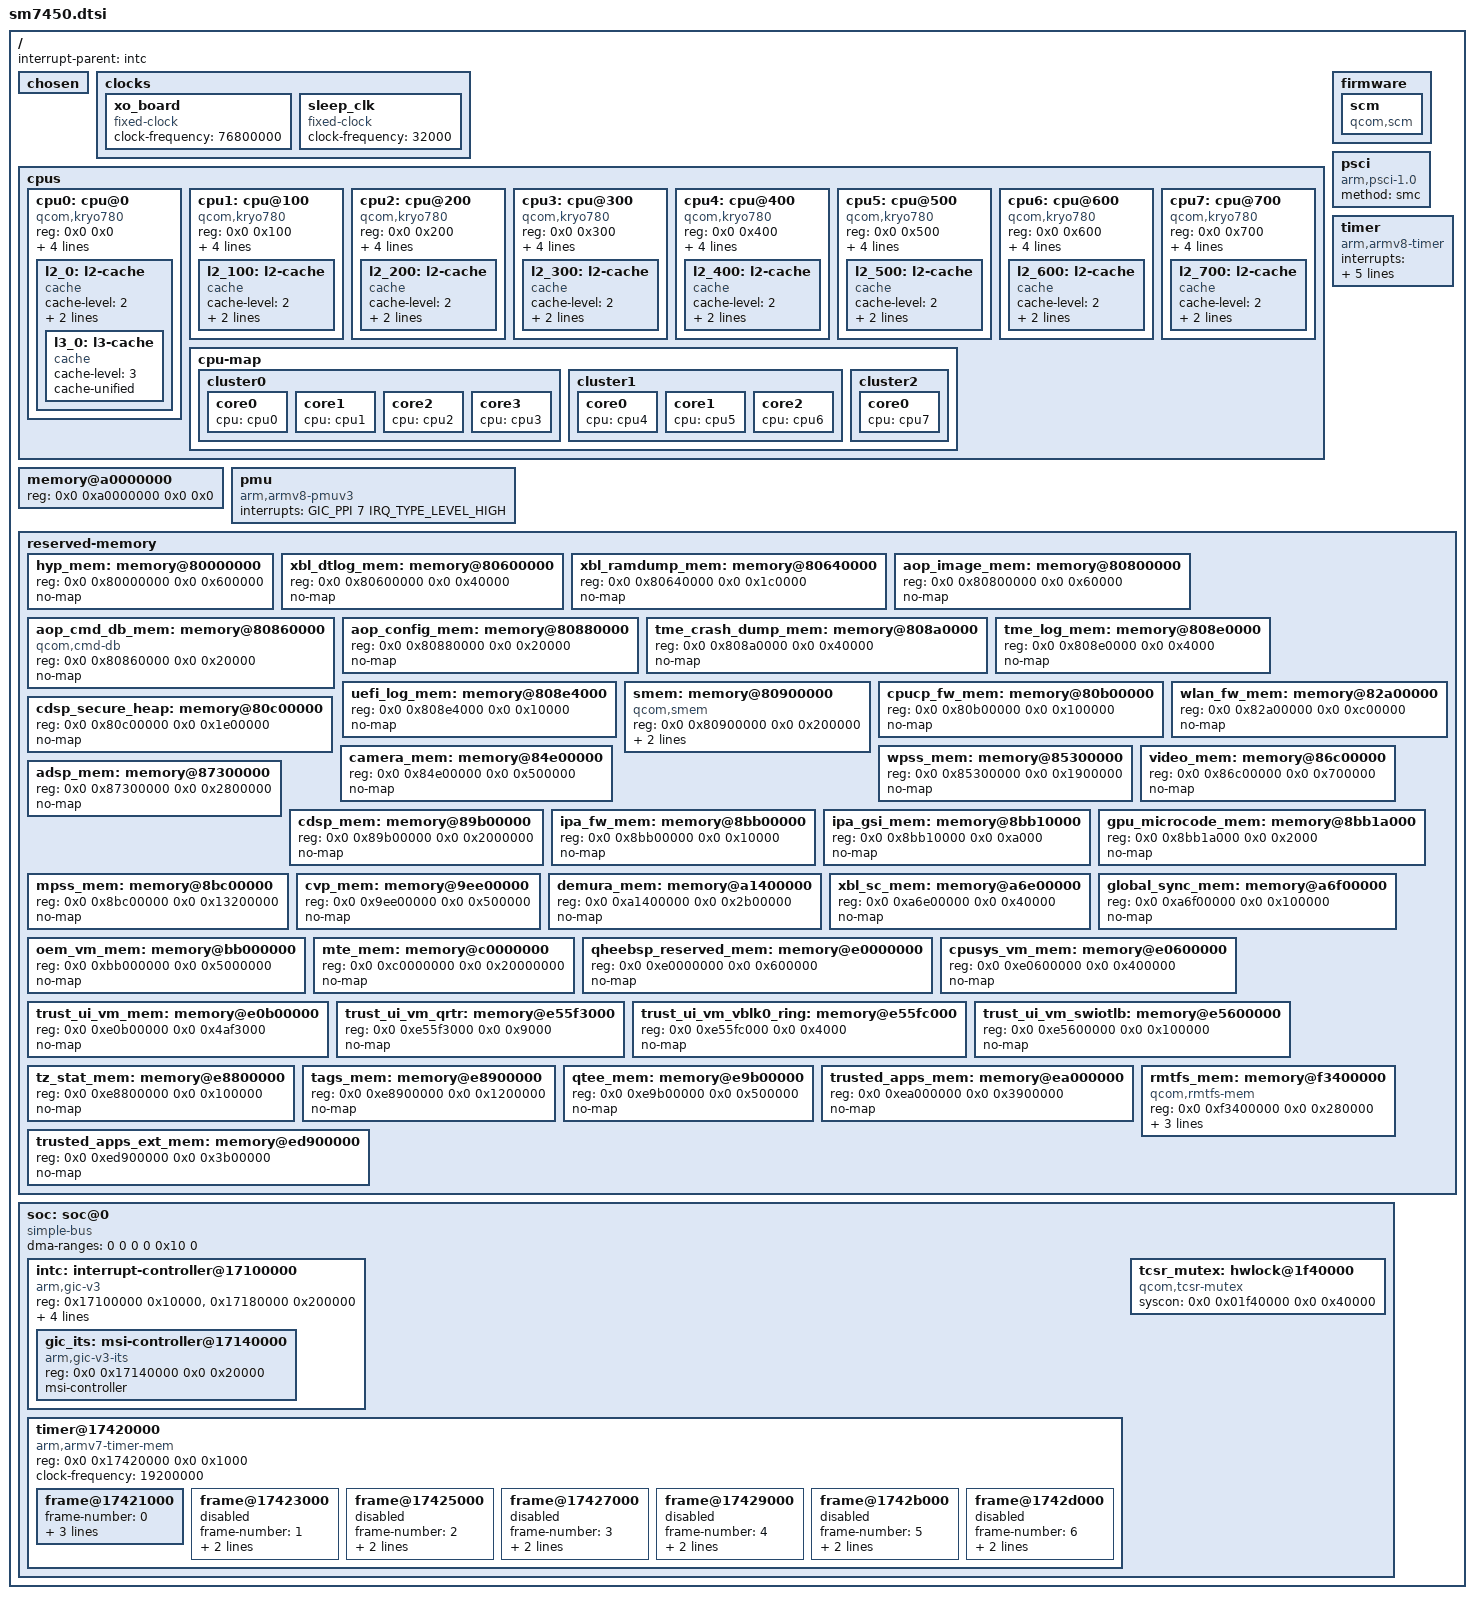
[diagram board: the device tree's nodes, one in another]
// SPDX-License-Identifier: GPL-2.0-only
/*
 * Copyright (c) 2025, Jens Reidel <adrian@travitia.xyz>
 */

#include <dt-bindings/firmware/qcom,scm.h>
#include <dt-bindings/interrupt-controller/arm-gic.h>

/ {
	interrupt-parent = <&intc>;

	#address-cells = <2>;
	#size-cells = <2>;

	chosen { };

	clocks {
		xo_board: xo_board {
			compatible = "fixed-clock";
			clock-frequency = <76800000>;
			#clock-cells = <0>;
		};

		sleep_clk: sleep_clk {
			compatible = "fixed-clock";
			clock-frequency = <32000>;
			#clock-cells = <0>;
		};
	};

	cpus {
		#address-cells = <2>;
		#size-cells = <0>;

		cpu0: cpu@0 {
			device_type = "cpu";
			compatible = "qcom,kryo780";
			reg = <0x0 0x0>;
			enable-method = "psci";
			capacity-dmips-mhz = <1024>;
			dynamic-power-coefficient = <100>;
			next-level-cache = <&l2_0>;
			#cooling-cells = <2>;
			l2_0: l2-cache {
				compatible = "cache";
				cache-level = <2>;
				cache-unified;
				next-level-cache = <&l3_0>;
				l3_0: l3-cache {
					compatible = "cache";
					cache-level = <3>;
					cache-unified;
				};
			};
		};

		cpu1: cpu@100 {
			device_type = "cpu";
			compatible = "qcom,kryo780";
			reg = <0x0 0x100>;
			enable-method = "psci";
			capacity-dmips-mhz = <1024>;
			dynamic-power-coefficient = <100>;
			next-level-cache = <&l2_100>;
			#cooling-cells = <2>;
			l2_100: l2-cache {
				compatible = "cache";
				cache-level = <2>;
				cache-unified;
				next-level-cache = <&l3_0>;
			};
		};

		cpu2: cpu@200 {
			device_type = "cpu";
			compatible = "qcom,kryo780";
			reg = <0x0 0x200>;
			enable-method = "psci";
			capacity-dmips-mhz = <1024>;
			dynamic-power-coefficient = <100>;
			next-level-cache = <&l2_200>;
			#cooling-cells = <2>;
			l2_200: l2-cache {
				compatible = "cache";
				cache-level = <2>;
				cache-unified;
				next-level-cache = <&l3_0>;
			};
		};

		cpu3: cpu@300 {
			device_type = "cpu";
			compatible = "qcom,kryo780";
			reg = <0x0 0x300>;
			enable-method = "psci";
			capacity-dmips-mhz = <1024>;
			dynamic-power-coefficient = <100>;
			next-level-cache = <&l2_300>;
			#cooling-cells = <2>;
			l2_300: l2-cache {
				compatible = "cache";
				cache-level = <2>;
				cache-unified;
				next-level-cache = <&l3_0>;
			};
		};

		cpu4: cpu@400 {
			device_type = "cpu";
			compatible = "qcom,kryo780";
			reg = <0x0 0x400>;
			enable-method = "psci";
			capacity-dmips-mhz = <2253>;
			dynamic-power-coefficient = <260>;
			next-level-cache = <&l2_400>;
			#cooling-cells = <2>;
			l2_400: l2-cache {
				compatible = "cache";
				cache-level = <2>;
				cache-unified;
				next-level-cache = <&l3_0>;
			};
		};

		cpu5: cpu@500 {
			device_type = "cpu";
			compatible = "qcom,kryo780";
			reg = <0x0 0x500>;
			enable-method = "psci";
			capacity-dmips-mhz = <2253>;
			dynamic-power-coefficient = <260>;
			next-level-cache = <&l2_500>;
			#cooling-cells = <2>;
			l2_500: l2-cache {
				compatible = "cache";
				cache-level = <2>;
				cache-unified;
				next-level-cache = <&l3_0>;
			};
		};

		cpu6: cpu@600 {
			device_type = "cpu";
			compatible = "qcom,kryo780";
			reg = <0x0 0x600>;
			enable-method = "psci";
			capacity-dmips-mhz = <2253>;
			dynamic-power-coefficient = <260>;
			next-level-cache = <&l2_600>;
			#cooling-cells = <2>;
			l2_600: l2-cache {
				compatible = "cache";
				cache-level = <2>;
				cache-unified;
				next-level-cache = <&l3_0>;
			};
		};

		cpu7: cpu@700 {
			device_type = "cpu";
			compatible = "qcom,kryo780";
			reg = <0x0 0x700>;
			enable-method = "psci";
			capacity-dmips-mhz = <2386>;
			dynamic-power-coefficient = <396>;
			next-level-cache = <&l2_700>;
			#cooling-cells = <2>;
			l2_700: l2-cache {
				compatible = "cache";
				cache-level = <2>;
				cache-unified;
				next-level-cache = <&l3_0>;
			};
		};

		cpu-map {
			cluster0 {
				core0 {
					cpu = <&cpu0>;
				};

				core1 {
					cpu = <&cpu1>;
				};

				core2 {
					cpu = <&cpu2>;
				};

				core3 {
					cpu = <&cpu3>;
				};
			};

			cluster1 {
				core0 {
					cpu = <&cpu4>;
				};

				core1 {
					cpu = <&cpu5>;
				};

				core2 {
					cpu = <&cpu6>;
				};
			};

			cluster2 {
				core0 {
					cpu = <&cpu7>;
				};
			};
		};
	};

	firmware {
		scm {
			compatible = "qcom,scm";
		};
	};

	memory@a0000000 {
		device_type = "memory";
		/* We expect the bootloader to fill in the size */
		reg = <0x0 0xa0000000 0x0 0x0>;
	};

	pmu {
		compatible = "arm,armv8-pmuv3";
		interrupts = <GIC_PPI 7 IRQ_TYPE_LEVEL_HIGH>;
	};

	psci {
		compatible = "arm,psci-1.0";
		method = "smc";
	};

	timer {
		compatible = "arm,armv8-timer";
		interrupts = <GIC_PPI 13 (GIC_CPU_MASK_SIMPLE(8) | IRQ_TYPE_LEVEL_LOW)>,
			     <GIC_PPI 14 (GIC_CPU_MASK_SIMPLE(8) | IRQ_TYPE_LEVEL_LOW)>,
			     <GIC_PPI 11 (GIC_CPU_MASK_SIMPLE(8) | IRQ_TYPE_LEVEL_LOW)>,
			     <GIC_PPI 12 (GIC_CPU_MASK_SIMPLE(8) | IRQ_TYPE_LEVEL_LOW)>;
		clock-frequency = <19200000>;
	};

	reserved-memory {
		#address-cells = <2>;
		#size-cells = <2>;
		ranges;

		hyp_mem: memory@80000000 {
			reg = <0x0 0x80000000 0x0 0x600000>;
			no-map;
		};

		xbl_dtlog_mem: memory@80600000 {
			reg = <0x0 0x80600000 0x0 0x40000>;
			no-map;
		};

		xbl_ramdump_mem: memory@80640000 {
			reg = <0x0 0x80640000 0x0 0x1c0000>;
			no-map;
		};

		aop_image_mem: memory@80800000 {
			reg = <0x0 0x80800000 0x0 0x60000>;
			no-map;
		};

		aop_cmd_db_mem: memory@80860000 {
			compatible = "qcom,cmd-db";
			reg = <0x0 0x80860000 0x0 0x20000>;
			no-map;
		};

		aop_config_mem: memory@80880000 {
			reg = <0x0 0x80880000 0x0 0x20000>;
			no-map;
		};

		tme_crash_dump_mem: memory@808a0000 {
			reg = <0x0 0x808a0000 0x0 0x40000>;
			no-map;
		};

		tme_log_mem: memory@808e0000 {
			reg = <0x0 0x808e0000 0x0 0x4000>;
			no-map;
		};

		uefi_log_mem: memory@808e4000 {
			reg = <0x0 0x808e4000 0x0 0x10000>;
			no-map;
		};

		/* secdata region can be reused by apps */
		smem: memory@80900000 {
			compatible = "qcom,smem";
			reg = <0x0 0x80900000 0x0 0x200000>;
			hwlocks = <&tcsr_mutex 3>;
			no-map;
		};

		cpucp_fw_mem: memory@80b00000 {
			reg = <0x0 0x80b00000 0x0 0x100000>;
			no-map;
		};

		cdsp_secure_heap: memory@80c00000 {
			reg = <0x0 0x80c00000 0x0 0x1e00000>;
			no-map;
		};

		wlan_fw_mem: memory@82a00000 {
			reg = <0x0 0x82a00000 0x0 0xc00000>;
			no-map;
		};

		camera_mem: memory@84e00000 {
			reg = <0x0 0x84e00000 0x0 0x500000>;
			no-map;
		};

		wpss_mem: memory@85300000 {
			reg = <0x0 0x85300000 0x0 0x1900000>;
			no-map;
		};

		video_mem: memory@86c00000 {
			reg = <0x0 0x86c00000 0x0 0x700000>;
			no-map;
		};

		adsp_mem: memory@87300000 {
			reg = <0x0 0x87300000 0x0 0x2800000>;
			no-map;
		};

		cdsp_mem: memory@89b00000 {
			reg = <0x0 0x89b00000 0x0 0x2000000>;
			no-map;
		};

		ipa_fw_mem: memory@8bb00000 {
			reg = <0x0 0x8bb00000 0x0 0x10000>;
			no-map;
		};

		ipa_gsi_mem: memory@8bb10000 {
			reg = <0x0 0x8bb10000 0x0 0xa000>;
			no-map;
		};

		gpu_microcode_mem: memory@8bb1a000 {
			reg = <0x0 0x8bb1a000 0x0 0x2000>;
			no-map;
		};

		mpss_mem: memory@8bc00000 {
			reg = <0x0 0x8bc00000 0x0 0x13200000>;
			no-map;
		};

		cvp_mem: memory@9ee00000 {
			reg = <0x0 0x9ee00000 0x0 0x500000>;
			no-map;
		};

		/* TODO: This is in the UEFI but I cannot figure out what it is */
		demura_mem: memory@a1400000 {
			reg = <0x0 0xa1400000 0x0 0x2b00000>;
			no-map;
		};

		xbl_sc_mem: memory@a6e00000 {
			reg = <0x0 0xa6e00000 0x0 0x40000>;
			no-map;
		};

		global_sync_mem: memory@a6f00000 {
			reg = <0x0 0xa6f00000 0x0 0x100000>;
			no-map;
		};

		/* uefi region can be reused by APPS */

		/* Linux kernel image is loaded at 0xa0000000 */

		oem_vm_mem: memory@bb000000 {
			reg = <0x0 0xbb000000 0x0 0x5000000>;
			no-map;
		};

		mte_mem: memory@c0000000 {
			reg = <0x0 0xc0000000 0x0 0x20000000>;
			no-map;
		};

		qheebsp_reserved_mem: memory@e0000000 {
			reg = <0x0 0xe0000000 0x0 0x600000>;
			no-map;
		};

		cpusys_vm_mem: memory@e0600000 {
			reg = <0x0 0xe0600000 0x0 0x400000>;
			no-map;
		};

		trust_ui_vm_mem: memory@e0b00000 {
			reg = <0x0 0xe0b00000 0x0 0x4af3000>;
			no-map;
		};

		trust_ui_vm_qrtr: memory@e55f3000 {
			reg = <0x0 0xe55f3000 0x0 0x9000>;
			no-map;
		};

		trust_ui_vm_vblk0_ring: memory@e55fc000 {
			reg = <0x0 0xe55fc000 0x0 0x4000>;
			no-map;
		};

		trust_ui_vm_swiotlb: memory@e5600000 {
			reg = <0x0 0xe5600000 0x0 0x100000>;
			no-map;
		};

		tz_stat_mem: memory@e8800000 {
			reg = <0x0 0xe8800000 0x0 0x100000>;
			no-map;
		};

		tags_mem: memory@e8900000 {
			reg = <0x0 0xe8900000 0x0 0x1200000>;
			no-map;
		};

		qtee_mem: memory@e9b00000 {
			reg = <0x0 0xe9b00000 0x0 0x500000>;
			no-map;
		};

		trusted_apps_mem: memory@ea000000 {
			reg = <0x0 0xea000000 0x0 0x3900000>;
			no-map;
		};

		trusted_apps_ext_mem: memory@ed900000 {
			reg = <0x0 0xed900000 0x0 0x3b00000>;
			no-map;
		};

		/* TODO: Very likely device specific */
		rmtfs_mem: memory@f3400000 {
			compatible = "qcom,rmtfs-mem";
			reg = <0x0 0xf3400000 0x0 0x280000>;
			no-map;

			qcom,client-id = <1>;
			qcom,vmid = <QCOM_SCM_VMID_MSS_MSA>;
		};
	};

	soc: soc@0 {
		#address-cells = <2>;
		#size-cells = <2>;
		ranges = <0 0 0 0 0x10 0>;
		dma-ranges = <0 0 0 0 0x10 0>;
		compatible = "simple-bus";

		intc: interrupt-controller@17100000 {
			compatible = "arm,gic-v3";
			reg = <0x17100000 0x10000>,     /* GICD */
			      <0x17180000 0x200000>;    /* GICR * 8 */
			interrupts = <GIC_PPI 9 IRQ_TYPE_LEVEL_LOW>;
			#interrupt-cells = <3>;
			interrupt-controller;
			#redistributor-regions = <1>;
			redistributor-stride = <0x0 0x40000>;
			#address-cells = <2>;
			#size-cells = <2>;
			ranges;

			gic_its: msi-controller@17140000 {
				compatible = "arm,gic-v3-its";
				reg = <0x0 0x17140000 0x0 0x20000>;
				msi-controller;
				#msi-cells = <1>;
			};
		};

		timer@17420000 {
			compatible = "arm,armv7-timer-mem";
			#address-cells = <1>;
			#size-cells = <1>;
			ranges = <0 0 0 0x20000000>;
			reg = <0x0 0x17420000 0x0 0x1000>;
			clock-frequency = <19200000>;

			frame@17421000 {
				frame-number = <0>;
				interrupts = <GIC_SPI 8 IRQ_TYPE_LEVEL_HIGH>,
					     <GIC_SPI 6 IRQ_TYPE_LEVEL_HIGH>;
				reg = <0x17421000 0x1000>,
				      <0x17422000 0x1000>;
			};

			frame@17423000 {
				frame-number = <1>;
				interrupts = <GIC_SPI 9 IRQ_TYPE_LEVEL_HIGH>;
				reg = <0x17423000 0x1000>;
				status = "disabled";
			};

			frame@17425000 {
				frame-number = <2>;
				interrupts = <GIC_SPI 10 IRQ_TYPE_LEVEL_HIGH>;
				reg = <0x17425000 0x1000>;
				status = "disabled";
			};

			frame@17427000 {
				frame-number = <3>;
				interrupts = <GIC_SPI 11 IRQ_TYPE_LEVEL_HIGH>;
				reg = <0x17427000 0x1000>;
				status = "disabled";
			};

			frame@17429000 {
				frame-number = <4>;
				interrupts = <GIC_SPI 12 IRQ_TYPE_LEVEL_HIGH>;
				reg = <0x17429000 0x1000>;
				status = "disabled";
			};

			frame@1742b000 {
				frame-number = <5>;
				interrupts = <GIC_SPI 13 IRQ_TYPE_LEVEL_HIGH>;
				reg = <0x1742b000 0x1000>;
				status = "disabled";
			};

			frame@1742d000 {
				frame-number = <6>;
				interrupts = <GIC_SPI 14 IRQ_TYPE_LEVEL_HIGH>;
				reg = <0x1742d000 0x1000>;
				status = "disabled";
			};
		};

		tcsr_mutex: hwlock@1f40000 {
			compatible = "qcom,tcsr-mutex";
			syscon = <0x0 0x01f40000 0x0 0x40000>;
			#hwlock-cells = <1>;
		};
	};
};
